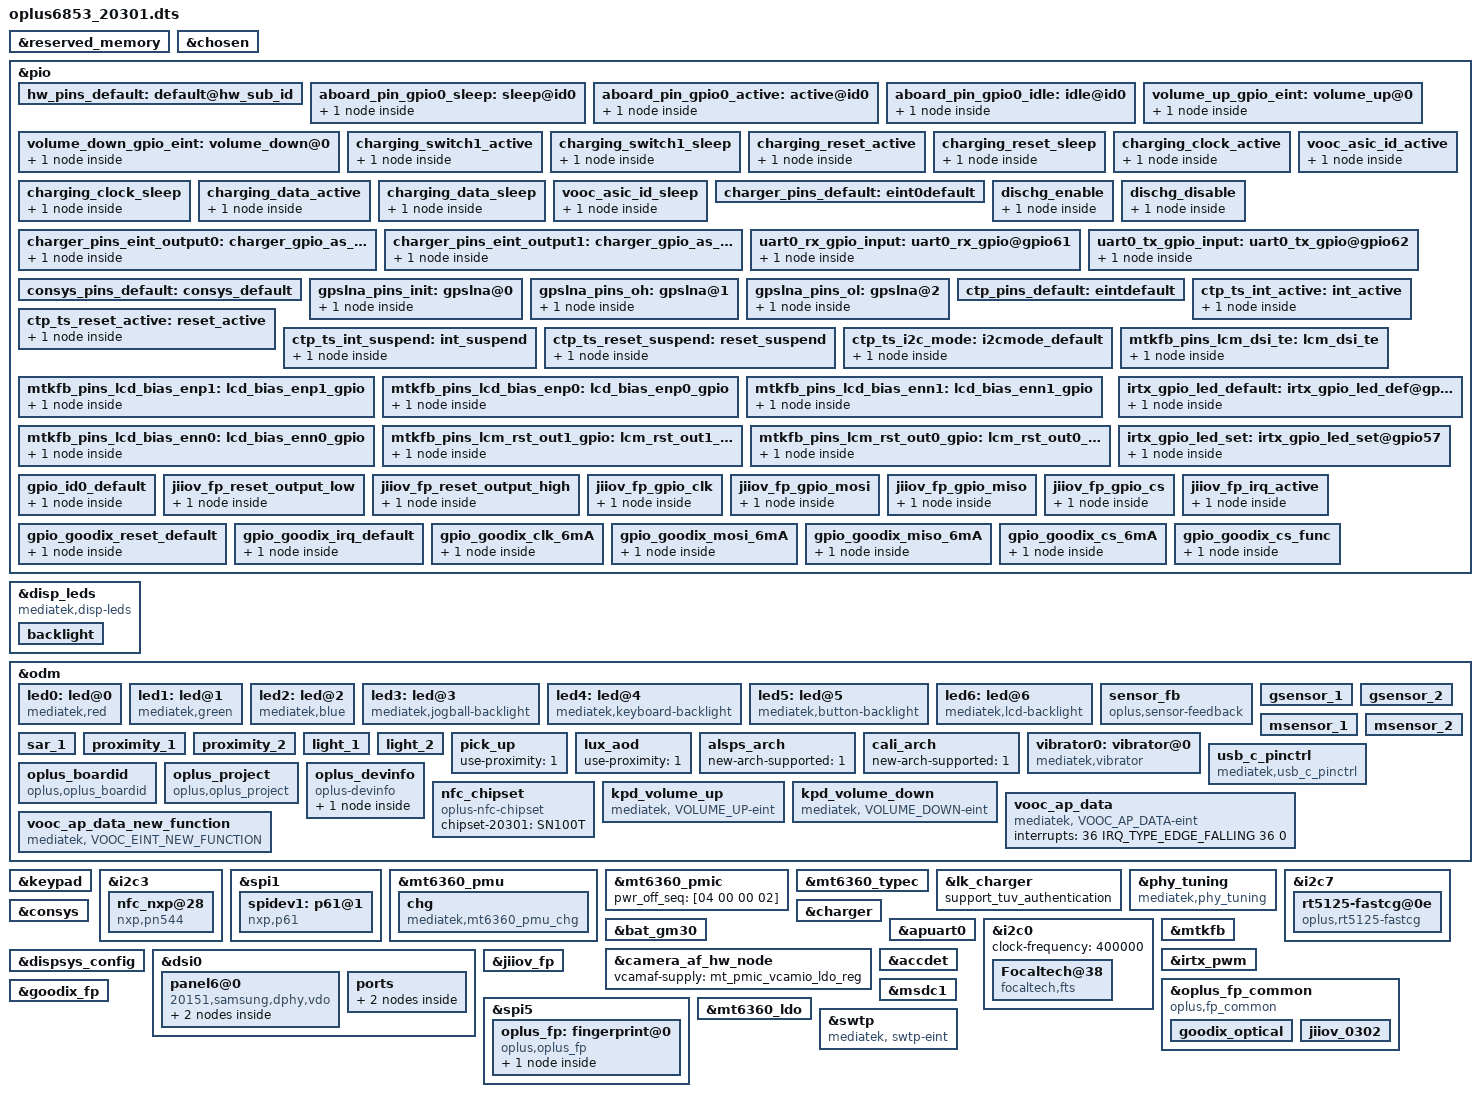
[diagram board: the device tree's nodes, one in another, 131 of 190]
/*
 * Mediatek's mt6853 SoC device tree source
 *
 * Copyright (C) 2016 MediaTek Inc.
 *
 * This program is free software; you can redistribute it and/or modify
 * it under the terms of the GNU General Public License version 2 as
 * published by the Free Software Foundation.
 *
 * This program is distributed in the hope that it will be useful,
 * but WITHOUT ANY WARRANTY; without even the implied warranty of
 * MERCHANTABILITY or FITNESS FOR A PARTICULAR PURPOSE.
 * See http://www.gnu.org/licenses/gpl-2.0.html for more details.
 */
/dts-v1/;
/plugin/;
#include <dt-bindings/interrupt-controller/irq.h>
#include <dt-bindings/interrupt-controller/arm-gic.h>
#include <dt-bindings/pinctrl/mt6853-pinfunc.h>

&reserved_memory {
};

/* chosen */
&chosen {

	atag,videolfb-fb_base_l = <0x7e605000>;
	atag,videolfb-fb_base_h = <0x0>;
	atag,videolfb-islcmfound = <1>;
	atag,videolfb-islcm_inited = <0>;
	atag,videolfb-fps= <6000>;
	atag,videolfb-vramSize= <0x1be0000>;
	atag,videolfb-lcmname=
		"nt35595_fhd_dsi_cmd_truly_nt50358_drv";
};
&pio {
        hw_pins_default:default@hw_sub_id {
        };

        aboard_pin_gpio0_sleep:sleep@id0 {
                pins_cmd_dat {
                        pinmux = <PINMUX_GPIO91__FUNC_GPIO91>;
                        slew-rate = <0>;
                        bias-pull-down;
                        input-enable;
                };
        };

        aboard_pin_gpio0_active:active@id0 {
                pins_cmd_dat {
                        pinmux = <PINMUX_GPIO91__FUNC_GPIO91>;
                        slew-rate = <0>;
                        bias-pull-up;
                        input-enable;
                };
        };

        aboard_pin_gpio0_idle:idle@id0 {
                pins_cmd_dat {
                        pinmux = <PINMUX_GPIO91__FUNC_GPIO91>;
                        slew-rate = <0>;
                        bias-disable;
                        input-enable;
                };
        };
};

&disp_leds {
	compatible = "mediatek,disp-leds";
	backlight {
		label = "lcd-backlight";
		max-brightness = <4095>;
		led-bits = <12>;
		trans-bits = <12>;
		default-state = "on";
	};
};

&odm {
	led0:led@0 {
		compatible = "mediatek,red";
		led_mode = <0>;
		data = <1>;
		pwm_config = <0 0 0 0 0>;
	};
	led1:led@1 {
		compatible = "mediatek,green";
		led_mode = <0>;
		data = <1>;
		pwm_config = <0 0 0 0 0>;
	};
	led2:led@2 {
		compatible = "mediatek,blue";
		led_mode = <0>;
		data = <1>;
		pwm_config = <0 0 0 0 0>;
	};
	led3:led@3 {
		compatible = "mediatek,jogball-backlight";
		led_mode = <0>;
		data = <1>;
		pwm_config = <0 0 0 0 0>;
	};
	led4:led@4 {
		compatible = "mediatek,keyboard-backlight";
		led_mode = <0>;
		data = <1>;
		pwm_config = <0 0 0 0 0>;
	};
	led5:led@5 {
		compatible = "mediatek,button-backlight";
		led_mode = <0>;
		data = <1>;
		pwm_config = <0 0 0 0 0>;
	};
	led6:led@6 {
		compatible = "mediatek,lcd-backlight";
		led_mode = <4>;
		data = <1>;
		pwm_config = <0 1 0 0 0>;
	};

	sensor_fb: sensor_fb {
		compatible = "oplus,sensor-feedback";
	};

	/*
	enum {
		LIS3DH,
		LSM6DS3,
		BMI160,
		LIS2HH12,
		LSM6DSM,
		BMI2XY,
		LSM6DSO,
		ICM4X6XX,
	};
	*/
	gsensor_1: gsensor_1 {
		status = "okay";
		sensor_name = <2>;//BMI160
		device_name = "bmi160";
		i2c_num = <2>;
		i2c_addr = <0>;
		direction = <3>;
		eint_num = <3>;
		step_count_7_en = <1>;
		config_miso = <1>;
		correct_y_bias = <0>;
		gyro_cali_version= <2>;
		acc_cali_range= <250 250 250>; //250mg
		gyro_cali_range= <350>;
	};

	gsensor_2: gsensor_2 {
		status = "okay";
		sensor_name = <4>;//LSM6DS3_c
		device_name = "lsm6dsm";
		i2c_num = <2>;
		i2c_addr = <0>;
		direction = <0>;
		eint_num = <3>;
		gyro_cali_version= <2>;
		acc_cali_range= <200 200 200>; //250mg
		gyro_cali_range= <700>;
	};
	/*
	enum {
		AKM09911,
		MMC3530,
		MMC5603,
		MXG4300,
	};
	*/
	msensor_1: msensor_1 {
		status = "okay";
		sensor_name = <0>;//AKM09911
		i2c_num = <0>;
		i2c_addr = <12>;
		direction = <5>;
		eint_num = <0>;
		soft-mag-parameter = <8507 0 1922 0 15 1 640 0 10513 0 39 1 1482 0 281 1 10130 0>;
	};
	msensor_2: msensor_2 {
		status = "okay";
		sensor_name = <3>;//MXG4300
		i2c_num = <0>;
		i2c_addr = <12>;
		direction = <5>;
		eint_num = <0>;
		soft-mag-parameter = <10000 0 0 0 0 0 0 0 10000 0 0 0 0 0 0 0 10000 0>;
	};

	/*
	enum {
		SX933x
	};
	*/
	sar_1: sar_1 {
		status = "okay";
		sensor_name = <0>;//SX933x
		i2c_num = <0>;
		i2c_addr = <40>;
		direction = <4>;
		eint_num = <13>;
		channel_num = <2>;
		channel_0_min = <4232>;
		channel_0_max = <6348>;
		channel_1_min = <2697>;
		channel_1_max = <4045>;
		channel_2_min = <0>;
		channel_2_max = <70000>;
		channel_3_min = <0>;
		channel_3_max = <70000>;
	};

	/*
	enum {
		TMD2725,
		APSD9922,
		STK3335,
		STK3331,
		STK2232,
		TCS3701,
		STK32600,
	};
	*/
	proximity_1: proximity_1 {
		status = "okay";
		sensor_name = <6>;//STK32600
		i2c_num = <0>;
		i2c_addr = <72>;
		direction = <4>;
		eint_num = <2>;
		low_step = <300>;
		high_step = <400>;
		low_limit = <650>;
		high_limit = <1050>;
		dirty_low_step = <300>;
		dirty_high_step = <400>;
		ps_dirty_limit = <1800>;
		ps_ir_limit = <2000>;
		ps_adjust_min = <0>;
		ps_adjust_max = <1850>;
		sampling_count = <5>;
		step_max = <400>;
		step_min = <100>;
		step_div = <2000>;
		anti_shake_delta = <70>;
		dynamic_cali_max = <2000>;
		raw2offset_radio = <1000>;
		offset_max = <60000>;
		offset_range_min = <0>;
		offset_range_max = <65534>;
		force_cali_limit = <2000>;
		cali_jitter_limit = <20>;
		cal_offset_margin = <3000>;
		sensor-reg = <0x03 0x30>;
	};
	proximity_2: proximity_2 {
		status = "okay";
		sensor_name = <5>;//TCS3701
		i2c_num = <0>;
		i2c_addr = <57>;
		direction = <4>;
		eint_num = <2>;
		low_step = <300>;
		high_step = <400>;
		low_limit = <400>;
		high_limit = <600>;
		dirty_low_step = <100>;
		dirty_high_step = <150>;
		ps_dirty_limit = <1022>;
		ps_ir_limit = <500>;
		ps_adjust_min = <0>;
		ps_adjust_max = <600>;
		sampling_count = <5>;
		step_max = <400>;
		step_min = <110>;
		step_div = <1500>;
		anti_shake_delta = <80>;
		dynamic_cali_max = <1023>;
		raw2offset_radio = <31200>;
		offset_max = <250>;
		offset_range_min = <255>;
		offset_range_max = <255>;
		force_cali_limit = <2000>;
		cali_jitter_limit = <30>;
		cal_offset_margin = <120>;
	};
	light_1: light_1 {
		status = "okay";
		sensor_name = <6>;//STK32600
		i2c_num = <0>;
		i2c_addr = <72>;
		direction = <4>;
		eint_num = <2>;
		als_buffer_length =<8>;
		als_ratio = <105>;
		device_name = "stk32600";
		als_type = <2>;
		als_spectral_coefficient = <1000>;
	};
	light_2: light_2 {
		status = "okay";
		sensor_name = <5>;//TCS3701
		i2c_num = <0>;
		i2c_addr = <57>;
		direction = <4>;
		eint_num = <2>;
		als_buffer_length = <10>;
		als_ratio = <110>;
                device_name = "tcs3701";
	};
	pick_up: pick_up {
		status = "okay";
		use-proximity = <1>;
	};
	lux_aod: lux_aod {
		status = "okay";
		use-proximity = <1>;
	};
	alsps_arch: alsps_arch {
		status = "okay";
		new-arch-supported = <1>;
	};
	cali_arch: cali_arch {
		status = "okay";
		new-arch-supported = <1>;
	};
	vibrator0:vibrator@0 {
		compatible = "mediatek,vibrator";
		//#ifdef OPLUS_FEATURE_CHG_BASIC
		vib_timer = <30>;
		vib_limit = <0>;
		//#endif
		vib_vol= <9>;
	};
	usb_c_pinctrl:usb_c_pinctrl {
		compatible = "mediatek,usb_c_pinctrl";
	};
	oplus_boardid:oplus_boardid {
		compatible = "oplus,oplus_boardid";
		oplus_boardid,dtsino="20301";//only one u32
		oplus_boardid,pcbmask="0xffff";//all mask 0xffff
	};
	oplus_project:oplus_project {
		compatible = "oplus,oplus_project";
	};
	oplus_devinfo:oplus_devinfo {
		compatible = "oplus-devinfo";
		pinctrl-names = "default", "aboard_gpio0_sleep", "aboard_gpio0_active", "aboard_gpio0_idle";
		pinctrl-0 = <&hw_pins_default>;
		pinctrl-1 = <&aboard_pin_gpio0_sleep>;
		pinctrl-2 = <&aboard_pin_gpio0_active>;
		pinctrl-3 = <&aboard_pin_gpio0_idle>;
		main-sub {
			use_tristate_gpio;
			compatible = "hw-match, main-sub";
			aboard-gpio0 = <&pio 91 0x00>;
			aboard-patterns = <0 2 1>;	/*0[high-resistance] 1[pull-down] 2[pull-up]*/
			/*main board*/
			match-projects = <20151 20301 20302>;
		};
	};

//#ifdef OPLUS_FEATURE_NFC_CONSOFT
    nfc_chipset:nfc_chipset {
        compatible = "oplus-nfc-chipset";
        chipset-20301 = "SN100T";
    };
//#endif /* OPLUS_FEATURE_NFC_CONSOFT */

/*OPLUS_FEAUTRE_KEYPAD keypad start*/
	kpd_volume_up:kpd_volume_up {
		compatible = "mediatek, VOLUME_UP-eint";
		interrupt-parent = <&pio>;
		interrupts = <1 IRQ_TYPE_EDGE_FALLING 1 0>;
		debounce = <32000>;
		status = "okay";
	};

	kpd_volume_down:kpd_volume_down {
		compatible = "mediatek, VOLUME_DOWN-eint";
		interrupt-parent = <&pio>;
		interrupts = <80 IRQ_TYPE_EDGE_FALLING 80 0>;
		debounce = <32000>;
		status = "okay";
	};
/*OPLUS_FEAUTRE_KEYPAD keypad end*/
};
/*OPLUS_FEAUTRE_KEYPAD keypad start*/
&keypad {
	keypad,volume-up	= <&pio 1 0x00>;
	keypad,volume-down	= <&pio 80 0x00>;
	pinctrl-names = "volume_up_as_int", "volume_down_as_int";
	pinctrl-0 = <&volume_up_gpio_eint>;
	pinctrl-1 = <&volume_down_gpio_eint>;
	status = "okay";
};

//#ifdef OPLUS_FEATURE_NFC_BRINGUP
&i2c3 {
       status = "okay";
       nfc_nxp@28 {
               compatible = "nxp,pn544";
               reg = <0x28>;
               nxp,pn544-irq = <&pio 5 0x0>;
               nxp,pn544-ven = <&pio 175 0x0>;
               nxp,pn544-fw-dwnld = <&pio 140 0x0>;
               nxp,pn544-clkreq = <&pio 81 0x0>;
               interrupt-parent = <&pio>;
       };
};

&spi1 {
       status = "okay";
       #address-cells = <1>;
       #size-cells = <0>;
       spidev1: p61@1 {
       compatible = "nxp,p61";
       reg = <0>;
       spi-max-frequency = <19200000>;
       };
};
//#endif /* OPLUS_FEATURE_NFC_BRINGUP */

&pio {
	volume_up_gpio_eint:volume_up@0{
		pins_cmd_dat {
			pinmux = <PINMUX_GPIO1__FUNC_GPIO1>;
			slew-rate = <0>;  /*direction 0:in, 1:out*/
			input-enable;
		};
	};

	volume_down_gpio_eint:volume_down@0{
		pins_cmd_dat {
			pinmux = <PINMUX_GPIO80__FUNC_GPIO80>;
			slew-rate = <0>;  /*direction 0:in, 1:out*/
			input-enable;
		};
	};
};
/*OPLUS_FEAUTRE_KEYPAD keypad end*/

/* Charging Start */
&mt6360_pmu {
	mt6360,intr_gpio_num = <10>; /* direct defined GPIO num */
	mt6360,intr_gpio = <&pio 10 0x0>;
	disable_lpsd = <1>;
};

&mt6360_pmic {
	pwr_off_seq = [04 00 00 02];
};

&mt6360_typec {
	mt6360pd,intr_gpio_num = <9>; /* direct defined GPIO num */
	mt6360pd,intr_gpio = <&pio 9 0x0>;
};

&mt6360_pmu {
	chg {
		compatible = "mediatek,mt6360_pmu_chg";
		interrupt-parent = <&mt6360_pmu>;
		interrupts = <4 0>, <6 0>, <7 0>, <9 0>,
				<12 0>, <13 0>, <14 0>, <15 0>,
				<27 0>, <29 0>, <30 0>, <32 0>,
				<35 0>, <40 0>, <48 0>, <60 0>,
				<53 0>;
		interrupt-names = "chg_treg_evt", "chg_mivr_evt",
				"pwr_rdy_evt", "chg_batsysuv_evt",
				"chg_vsysuv_evt", "chg_vsysov_evt",
				"chg_vbatov_evt", "chg_vbusov_evt",
				"chg_tmri", "chg_adpbadi",
				"chg_rvpi",  "chg_aiccmeasl",
				"wdtmri", "pumpx_donei",
				"attachi", "chrdet_ext_evt",
				"hvdcp_det";
		io-channels = <&adc 0>, <&adc 1>, <&adc 3>, <&adc 4>,
				<&adc 5>, <&adc 6>, <&adc 8>, <&adc 10>;
		io-channel-names = "USBID", "VBUSDIV5", "VSYS", "VBAT",
				"IBUS", "IBAT", "TEMP_JC", "TS";
		chg_name = "primary_chg";
		ichg = <2000000>;               /* uA */
		aicr = <500000>;                /* uA */
		mivr = <4400000>;               /* uV */
		cv = <4350000>;                 /* uA */
		ieoc = <150000>;                /* uA */
		safety_timer = <12>;            /* hour */
		ircmp_resistor = <25000>;       /* uohm */
		ircmp_vclamp = <32000>;         /* uV */
		en_te = <1>;
		en_wdt = <1>;
		aicc_once = <1>;
		post_aicc = <1>;
		batoc_notify = <0>;
	};
};

/*#ifdef OPLUS_FEATURE_CHG_BASIC*/
&lk_charger{
	support_tuv_authentication;
};
/*#endif*/

&phy_tuning {
	compatible = "mediatek,phy_tuning";
	u2_vrt_ref = <7>;
	u2_term_ref = <6>;
	u2_enhance = <2>;

	host_u2_vrt_ref = <5>;
	host_u2_term_ref = <1>;
	host_u2_enhance = <1>;
};

&i2c7 {
	rt5125-fastcg@0e{
		status = "okay";
		compatible = "oplus,rt5125-fastcg";
		reg = <0x0e>;
		qcom,vooc_reply_mcu_bits = <7>;
		qcom,oplus_batt_4400mv;
		qcom,vooc-low-temp = <0>;
		qcom,vooc-high-temp = <430>;
		qcom,vooc-high-soc = <90>;
		qcom,vooc_cool_bat_volt = <3650>;
		qcom,vooc_little_cool_bat_volt = <3550>;
		qcom,vooc_normal_bat_volt = <3450>;
		qcom,vooc_warm_bat_volt = <3350>;

		qcom,vooc_cool_bat_suspend_volt = <3650>;
		qcom,vooc_little_cool_bat_suspend_volt = <3550>;
		qcom,vooc_normal_bat_suspend_volt = <3450>;
		qcom,vooc_warm_bat_suspend_volt = <3350>;
		qcom,vooc_fw_update_newmethod;
		qcom,vooc-fw-type = <2>;
		qcom,vooc_is_platform_gauge;
		qcom,vooc_multistep_adjust_current_support;
		qcom,vooc_multistep_initial_batt_temp = <1000>;
		qcom,vooc_strategy_normal_current = <0x0b>;

		qcom,vooc_strategy1_batt_high_temp0 = <410>;
		qcom,vooc_strategy1_batt_high_temp1 = <425>;
		qcom,vooc_strategy1_batt_high_temp2 = <435>;
		qcom,vooc_strategy1_batt_low_temp2 = <430>;
		qcom,vooc_strategy1_batt_low_temp1 = <410>;
		qcom,vooc_strategy1_batt_low_temp0 = <390>;

		qcom,vooc_strategy1_high_current0 = <0x07>;//4A
		qcom,vooc_strategy1_high_current1 = <0x05>;//3A
		qcom,vooc_strategy1_high_current2 = <0x04>;//2A
		qcom,vooc_strategy1_low_current2 = <0x05>;//3A
		qcom,vooc_strategy1_low_current1 = <0x09>;//5A
		qcom,vooc_strategy1_low_current0 = <0x0b>;//6A

		qcom,vooc_current_lvl = <1000
									1500
									2000
									2500
									3000
									3500
									4000
									4500
									5000
									5500
									6000
									6500
									7000
									7500
									8000
									8500
									9000
									9500
									10000
									10500
									11000
									11500
									12000
									12500>;

		pinctrl-names = "switch1_act_switch2_act", "switch1_sleep_switch2_sleep",
						"switch1_act_switch3_act", "switch1_sleep_switch3_sleep",
						"switch1_act_switch2_sleep", "switch1_sleep_switch2_act",
						"clock_active","clock_sleep",
						"data_active","data_sleep",
						"reset_active","reset_sleep",
						"vooc_asic_id_active","vooc_asic_id_sleep";
		pinctrl-0 = <&charging_switch1_active>;
		pinctrl-1 = <&charging_switch1_sleep>;
		pinctrl-2 = <&charging_switch1_active>;
		pinctrl-3 = <&charging_switch1_sleep>;
		pinctrl-4 = <&charging_switch1_active>;
		pinctrl-5 = <&charging_switch1_sleep>;
		pinctrl-6 = <&charging_clock_active>;
		pinctrl-7 = <&charging_clock_sleep>;
		pinctrl-8 = <&charging_data_active>;
		pinctrl-9 = <&charging_data_sleep>;
		pinctrl-10 = <&charging_reset_active>;
		pinctrl-11 = <&charging_reset_sleep>;
		pinctrl-12 = <&vooc_asic_id_active>;
		pinctrl-13 = <&vooc_asic_id_sleep>;

		qcom,charging_switch1-gpio 		= <&pio 32 0x00>;              //SW_CTRL
		//qcom,charging_switch1_ctr1-gpio 	= <&pio 148 0x00>;

		qcom,charging_reset-gpio 			= <&pio 132 0x00>;         //mcu_en
		qcom,charging_clock-gpio 			= <&pio 35 0x00>;          //ap_clk
		qcom,charging_data-gpio 			= <&pio 36 0x00>;          //ap_data
		qcom,vooc_asic_id-gpio				= <&pio 92 0x00>;
	};

};

&pio {
	charging_switch1_active: charging_switch1_active {
		pins_cmd_dat {
			pinmux = <PINMUX_GPIO32__FUNC_GPIO32>;
			slew-rate = <1>;
			output-high;
		};
	};

	charging_switch1_sleep: charging_switch1_sleep {
		pins_cmd_dat {
			pinmux = <PINMUX_GPIO32__FUNC_GPIO32>;
			slew-rate = <1>;
			output-low;
		};
	};

	/*charging_switch1_ctr1_active: charging_switch1_ctr1_active {
		pins_cmd_dat {
			pinmux = <PINMUX_GPIO127__FUNC_GPIO127>;
			slew-rate = <1>;
			output-high;
		};
	};
	charging_switch1_ctr1_sleep: charging_switch1_ctr1_sleep {
		pins_cmd_dat {
			pinmux = <PINMUX_GPIO127__FUNC_GPIO127>;
			slew-rate = <1>;
			output-low;
		};
	};*/

	charging_reset_active: charging_reset_active {
		pins_cmd_dat {
			pinmux = <PINMUX_GPIO132__FUNC_GPIO132>;
			slew-rate = <1>;
			output-high;
		};
	};

	charging_reset_sleep: charging_reset_sleep {
		pins_cmd_dat {
			pinmux = <PINMUX_GPIO132__FUNC_GPIO132>;
			slew-rate = <1>;
			output-low;
		};
	};

	charging_clock_active: charging_clock_active {
		pins_cmd_dat {
			pinmux = <PINMUX_GPIO35__FUNC_GPIO35>;
			slew-rate = <0>;
			bias-pull-up;
		};
	};

	charging_clock_sleep: charging_clock_sleep {
		pins_cmd_dat {
			pinmux = <PINMUX_GPIO35__FUNC_GPIO35>;
			slew-rate = <0>;
			bias-pull-down;
		};
	};

	charging_data_active: charging_data_active {
		pins_cmd_dat {
			pinmux = <PINMUX_GPIO36__FUNC_GPIO36>;
			slew-rate = <0>;
			bias-pull-down;
		};
	};

	charging_data_sleep: charging_data_sleep {
		pins_cmd_dat {
			pinmux = <PINMUX_GPIO36__FUNC_GPIO36>;
			slew-rate = <0>;
			bias-pull-down;
		};
	};

	vooc_asic_id_active: vooc_asic_id_active {
		pins_cmd_dat {
			pinmux = <PINMUX_GPIO92__FUNC_GPIO92>;
			input-enable;
			slew-rate = <0>;
			bias-pull-up;
		};
	};
	vooc_asic_id_sleep: vooc_asic_id_sleep {
		pins_cmd_dat {
			pinmux = <PINMUX_GPIO92__FUNC_GPIO92>;
			input-enable;
			slew-rate = <0>;
			bias-pull-down;
		};
	};

};

&odm {
	vooc_ap_data:vooc_ap_data {
		compatible = "mediatek, VOOC_AP_DATA-eint";
		interrupts = <36 IRQ_TYPE_EDGE_FALLING 36 0>;
	};
	vooc_ap_data_new_function:vooc_ap_data_new_function {
		compatible = "mediatek, VOOC_EINT_NEW_FUNCTION";
	};
	/*cp_low_current:cp_low_current {
		compatible = "mediatek, CP_LOW_CURRENT-eint";
		interrupts = <12 IRQ_TYPE_EDGE_FALLING 12 0>;
	};
	cp_low_current_new_function:cp_low_current_new_function {
		compatible = "mediatek,  CP_LOW_CURRENT_EINT_NEW_FUNCTION";
	};*/

};

&charger {
	io-channels =  <&auxadc 3>,<&auxadc 4>,
		<&auxadc 5>;
	io-channel-names = "auxadc3-chargeric_temp","auxadc4-usb_temp_v_l",
		"auxadc5-usb_temp_v_r";

	pinctrl-names = "default", "dischg_enable", "dischg_disable" ,"charger_gpio_as_output_low", "charger_gpio_as_output_high";
	pinctrl-0 = <&charger_pins_default>;
	pinctrl-1 = <&dischg_enable>;
	pinctrl-2 = <&dischg_disable>;
	pinctrl-3 = <&charger_pins_eint_output0>;      //USB_ON -> USB_SWITCH:(UART && USB)
	pinctrl-4 = <&charger_pins_eint_output1>;


	//for oplus chg framework:
	qcom,input_current_charger_ma = <2000>;
	qcom,input_current_usb_ma = <500>;
	qcom,input_current_cdp_ma = <1500>;
	qcom,input_current_led_ma = <1200>;
	qcom,input_current_led_ma_high = <1200>;
	qcom,input_current_led_ma_warm = <1500>;
	qcom,input_current_led_ma_normal = <2000>;
	qcom,input_current_led_ma_forcmcc = <500>;
	qcom,input_current_camera_ma = <2000>;
	qcom,input_current_calling_ma = <1500>;
	qcom,pd_input_current_charger_ma = <3000>;

	qcom,iterm_disabled = <0>;
	qcom,iterm_ma = <221>;
	qcom,recharge-mv = <100>;

	qcom,batt_capacity_mah = <4310>; /*typical capacity*/
	//qcom,batt_capacity_mah = <4220>; /*rated capacity*/

	qcom,removed_bat_decidegc = <190>;  /* < -19C */

	qcom,cold_bat_decidegc = <20>;  /* -2C ~ 0C */
	qcom,temp_cold_vfloat_mv = <3980>;
	qcom,temp_cold_fastchg_current_ma = <300>;

	qcom,little_cold_bat_decidegc = <0>;    /* 0C ~ 5C */
	qcom,temp_little_cold_vfloat_mv = <4435>;
	qcom,temp_little_cold_fastchg_current_ma_high = <1850>;
	qcom,temp_little_cold_fastchg_current_ma_low = <1100>;
	qcom,temp_little_cold_fastchg_current_ma = <1100>;
	qcom,pd_temp_little_cold_fastchg_current_ma_high = <1850>;
	qcom,pd_temp_little_cold_fastchg_current_ma_low = <1100>;

	qcom,cool_bat_decidegc = <50>;  /* 5C ~ 12C */
	qcom,temp_cool_vfloat_mv = <4435>;
	qcom,temp_cool_fastchg_current_ma_high = <2200>;
	qcom,temp_cool_fastchg_current_ma_low = <1850>;
	qcom,pd_temp_cool_fastchg_current_ma_high = <2600>;
	qcom,pd_temp_cool_fastchg_current_ma_low = <1850>;

	qcom,little_cool_bat_decidegc = <120>;  /* 12C ~ 16C */
	qcom,temp_little_cool_vfloat_mv = <4435>;
	qcom,temp_little_cool_fastchg_current_ma = <2200>;
	qcom,pd_temp_little_cool_fastchg_current_ma = <3200>;

	qcom,normal_bat_decidegc = <160>;       /* 16C ~ 45C */
	qcom,temp_normal_fastchg_current_ma = <2600>;
	qcom,temp_normal_vfloat_mv = <4435>;
	qcom,pd_temp_normal_fastchg_current_ma = <3200>;

	qcom,warm_bat_decidegc = <450>;         /* 45C ~ 53C */ /*8pin Bat Vooc project need add 3 degree C*/
	qcom,temp_warm_vfloat_mv = <4130>;
	qcom,temp_warm_fastchg_current_ma = <1100>;
	qcom,temp_warm_fastchg_current_ma_led_on = <500>;
	qcom,pd_temp_warm_fastchg_current_ma = <1100>;

	qcom,hot_bat_decidegc = <530>;  /* > 53C */

	qcom,non_standard_vfloat_mv = <3980>;
	qcom,non_standard_fastchg_current_ma = <512>;

	qcom,short_c_bat_cv_mv = <4330>;
	qcom,short_c_bat_vfloat_mv = <3800>;
	qcom,short_c_bat_fastchg_current_ma = <512>;
	qcom,short_c_bat_vfloat_sw_limit = <3750>;

	qcom,cold_vfloat_sw_limit = <3930>;
	qcom,little_cold_vfloat_sw_limit = <4385>;
	qcom,cool_vfloat_sw_limit = <4385>;
	qcom,little_cool_vfloat_sw_limit = <4385>;
	qcom,normal_vfloat_sw_limit = <4385>;
	qcom,warm_vfloat_sw_limit = <4080>;
	qcom,non_standard_vfloat_sw_limit = <3930>;

	qcom,max_chg_time_sec = <36000>;
	qcom,charger_hv_thr = <5900>;
	qcom,charger_recv_thr = <5500>;
	qcom,charger_lv_thr = <3400>;
	qcom,vbatt_full_thr = <4400>;
	qcom,vbatt_hv_thr = <4550>;

	qcom,vfloat_step_mv = <8>;
	qcom,non_standard_vfloat_over_sw_limit = <3990>;
	qcom,cold_vfloat_over_sw_limit = <3990>;
	qcom,little_cold_vfloat_over_sw_limit = <4445>;
	qcom,cool_vfloat_over_sw_limit = <4445>;
	qcom,little_cool_vfloat_over_sw_limit = <4445>;
	qcom,normal_vfloat_over_sw_limit = <4445>;
	qcom,warm_vfloat_over_sw_limit = <4140>;

	qcom,vbatt_power_off = <3300>;
	qcom,vbatt_soc_1 = <3410>;
	qcom,vooc_project = <1>;
	qcom,vbatt_num = <1>;
	qcom,internal_gauge_with_asic = <1>;
	qcom,ffc_support;
	qcom,chargerid_support;

	qcom,normal_vterm_hw_inc = <18>;
	qcom,non_normal_vterm_hw_inc = <18>;

	qcom,ff1_normal_fastchg_ma = <1400>;
	qcom,ff1_warm_fastchg_ma = <1500>;	/* 35C ~ 40c */
	qcom,ff1_exit_step_ma = <150>;
	qcom,ff1_warm_exit_step_ma = <150>;
	qcom,ffc2_normal_fastchg_ma = <1400>;/*16C~35c*/
	qcom,ffc2_warm_fastchg_ma = <1500>;	/* 35C ~ 40c */
	qcom,ffc2_temp_warm_decidegc = <350>;
	qcom,ffc2_temp_high_decidegc = <400>;
	qcom,ffc2_temp_low_decidegc = <160>;
	qcom,ffc2_exit_step_ma = <150>;
	qcom,ffc2_warm_exit_step_ma = <150>;

	qcom,ffc_normal_vfloat_sw_limit = <4485>;
	qcom,ffc2_normal_vfloat_sw_limit = <4485>;
	qcom,ffc_temp_normal_vfloat_mv = <4550>;
	qcom,ffc_normal_vfloat_over_sw_limit = <4550>;

	qcom,overchg_normal_fastchg_ma = <700>;/*16C~35c*/
	qcom,overchg_temp_warm_decidegc = <350>;
	qcom,overchg_warm_fastchg_ma = <750>;/*35C~40c*/
	qcom,overchg_temp_high_decidegc = <400>;

	qcom,overchg_normal_vfloat_sw_limit = <4450>;
	qcom,overchg_temp_normal_vfloat_mv = <4500>;
	qcom,overchg_normal_vfloat_over_sw_limit = <4500>;

	qcom,default_iterm_ma = <221>;
	qcom,default_temp_normal_fastchg_current_ma = <2000>;
	qcom,default_normal_vfloat_sw_limit = <4385>;
	qcom,default_temp_normal_vfloat_mv = <4435>;
	qcom,default_normal_vfloat_over_sw_limit = <4445>;

	//for control:
	//qcom,suspend_after_full;
	qcom,check_batt_full_by_sw;
	//qcom,external_gauge;
	qcom,chg_ctrl_by_calling;
	qcom,chg_ctrl_by_lcd;
	qcom,chg_ctrl_by_camera;
	qcom,sw_vfloat_over_protect_enable;
	qcom,support_ntc_01c_precision;
	qcom,smart_charging_screenoff;
	qcom,usbtemp_lowvbus_detect;
	qcom,vooc_show_ui_soc_decimal;
	qcom,ui_soc_decimal_speedmin = <20>;

	//GPIO config:
	qcom,chargerid_switch-gpio = <&pio 46 0x00>;
	qcom,dischg-gpio = <&pio 44 0x00>;
};

&bat_gm30 {
	FUELGAGUE_APPLY = <(1)>;
	IS_4450MV_BATTERY_SUPPORT = <(1)>;
	ENABLE_IS_FORCE_FULL = <1>;
	io-channels = <&auxadc 6>;
	io-channel-names = "auxadc6-batt_id_v";
	/*bat_id channel*/
	CAR_TUNE_VALUE = <(99)>;
	/*The resistance of PCB*/
	R_FG_VALUE = <(5)>;
	/*R_sense resistance*/
	g_FG_PSEUDO100_T0 = <(98)>;
/*	Pseudo 100% percentage at T0*/
	g_FG_PSEUDO100_T1 = <(98)>;
/*	Pseudo 100% percentage at T1*/
	g_FG_PSEUDO100_T2 = <(98)>;
/*	Pseudo 100% percentage at T2*/
	g_FG_PSEUDO100_T3 = <(94)>;
/*	Pseudo 100% percentage at T3*/
	#include "mediatek/bat_setting/mt6853_20151_battery_table.dtsi"
	#include "mediatek/bat_setting/mt6853_20151_battery_prop_dim2_ext.dtsi"
	/*zcv table*/
};

&pio {
	charger_pins_default: eint0default {
	};

	dischg_enable: dischg_enable {
		pins_cmd_dat {
			pinmux = <PINMUX_GPIO44__FUNC_GPIO44>;
			slew-rate = <1>;           //0:input direction 1:output direction
			//bias-pull-up = <00>;
			output-high;
		};
	};

	dischg_disable: dischg_disable {
		pins_cmd_dat {
			pinmux = <PINMUX_GPIO44__FUNC_GPIO44>;
			slew-rate = <1>;
			//bias-pull-down = <00>;
			output-low;
		};
	};

	charger_pins_eint_output0: charger_gpio_as_output_low {
		pins_cmd_dat {
			pinmux = <PINMUX_GPIO46__FUNC_GPIO46>;
			slew-rate = <1>;
			output-low;
		};
	};
	charger_pins_eint_output1: charger_gpio_as_output_high {
		pins_cmd_dat {
			pinmux = <PINMUX_GPIO46__FUNC_GPIO46>;
			slew-rate = <1>;
			output-high;
		};
	};

};

&apuart0 {
	pinctrl-names = "uart0_rx_gpio",
			"uart0_tx_gpio";
	pinctrl-0 = <&uart0_rx_gpio_input>;
	pinctrl-1 = <&uart0_tx_gpio_input>;
	status = "okay";
};

&pio {
	uart0_rx_gpio_input:uart0_rx_gpio@gpio61 {
		pins_cmd_dat {
			pinmux = <PINMUX_GPIO61__FUNC_GPIO61>;
			input-enable;
			slew-rate = <0>;
			bias-disable;
		};
	};
	uart0_tx_gpio_input:uart0_tx_gpio@gpio62 {
		pins_cmd_dat {
			pinmux = <PINMUX_GPIO62__FUNC_GPIO62>;
			input-enable;
			slew-rate = <0>;
			bias-disable;
		};
	};
};

/* Charging end  */

/* USB SWITCH GPIO start */
//&pio {
//	usb_default: usb_default {
//	};
//
//	gpio_redriver_c1_init: c1_init {
//		pins_cmd_dat {
//			pinmux = <PINMUX_GPIO41__FUNC_GPIO41>;
//			slew-rate = <1>;
//			output-low;
//		};
//	};
//
//	gpio_redriver_c1_low: c1_low {
//		pins_cmd_dat {
//			pinmux = <PINMUX_GPIO41__FUNC_GPIO41>;
//			slew-rate = <1>;
//			output-low;
//		};
//	};
//
//	gpio_redriver_c1_hiz: c1_highz {
//		pins_cmd_dat {
//			pinmux = <PINMUX_GPIO41__FUNC_GPIO41>;
//			slew-rate= <0>;
//			bias-disable;
//		};
//	};
//
//	gpio_redriver_c1_high: c1_high {
//		pins_cmd_dat {
//			pinmux = <PINMUX_GPIO41__FUNC_GPIO41>;
//			slew-rate = <1>;
//			output-high;
//		};
//	};
//
//	gpio_redriver_c2_init: c2_init {
//		pins_cmd_dat {
//			pinmux = <PINMUX_GPIO40__FUNC_GPIO40>;
//			slew-rate = <1>;
//			output-low;
//		};
//	};
//
//	gpio_redriver_c2_low: c2_low {
//		pins_cmd_dat {
//			pinmux = <PINMUX_GPIO40__FUNC_GPIO40>;
//			slew-rate = <1>;
//			output-low;
//		};
//	};
//
//	gpio_redriver_c2_hiz: c2_highz {
//		pins_cmd_dat {
//			pinmux = <PINMUX_GPIO40__FUNC_GPIO40>;
//			slew-rate= <0>;
//			bias-disable;
//		};
//	};
//
//	gpio_redriver_c2_high: c2_high {
//		pins_cmd_dat {
//			pinmux = <PINMUX_GPIO40__FUNC_GPIO40>;
//			slew-rate = <1>;
//			output-high;
//		};
//	};
//
//	gpio_u3_switch_sel1: u3_sw_sel1 {
//		pins_cmd_dat {
//			pinmux = <PINMUX_GPIO11__FUNC_GPIO11>;
//			slew-rate = <1>;
//			output-low;
//		};
//	};
//
//	gpio_u3_switch_sel2: u3_sw_sel2 {
//		pins_cmd_dat {
//			pinmux = <PINMUX_GPIO11__FUNC_GPIO11>;
//			slew-rate = <1>;
//			output-high;
//		};
//	};
//
//	gpio_u3_switch_enable: u3_sw_en {
//	};
//
//	gpio_u3_switch_disable: u3_sw_dis {
//	};
//};
//
//&usb_c_pinctrl {
//	pinctrl-names = "usb_default",
//		"redrv_c1_init",
//		"redrv_c1_low",
//		"redrv_c1_hiz",
//		"redrv_c1_high",
//		"redrv_c2_init",
//		"redrv_c2_low",
//		"redrv_c2_hiz",
//		"redrv_c2_high",
//		"switch_sel1",
//		"switch_sel2",
//		"switch_enable",
//		"switch_disable";
//
//	pinctrl-0 = <&usb_default>;
//	pinctrl-1 = <&gpio_redriver_c1_init>;
//	pinctrl-2 = <&gpio_redriver_c1_low>;
//	pinctrl-3 = <&gpio_redriver_c1_hiz>;
//	pinctrl-4 = <&gpio_redriver_c1_high>;
//	pinctrl-5 = <&gpio_redriver_c2_init>;
//	pinctrl-6 = <&gpio_redriver_c2_low>;
//	pinctrl-7 = <&gpio_redriver_c2_hiz>;
//	pinctrl-8 = <&gpio_redriver_c2_high>;
//	pinctrl-9 = <&gpio_u3_switch_sel1>;
//	pinctrl-10 = <&gpio_u3_switch_sel2>;
//	pinctrl-11 = <&gpio_u3_switch_enable>;
//	pinctrl-12 = <&gpio_u3_switch_disable>;
//	status = "okay";
//
//	usb_switch-data {
//		en_pin_num = <0>;
//		en_pin_val = <0>;
//		sel_pin_num = <11>;
//		sel_pin_val = <1>;
//		c1_pin_num = <41>;
//		c1_pin_val = <2>;
//		c2_pin_num = <40>;
//		c2_pin_val = <1>;
//	};
//};
/* USB SWITCH GPIO end */

/* CONSYS GPIO standardization */
&pio {
	consys_pins_default: consys_default {
	};
	gpslna_pins_init: gpslna@0 {
		pins_cmd_dat {
			pinmux = <PINMUX_GPIO87__FUNC_GPIO87>;
			output-low;
		};
	};
	gpslna_pins_oh: gpslna@1 {
		pins_cmd_dat {
			pinmux = <PINMUX_GPIO87__FUNC_GPS_L1_ELNA_EN>;
		};
	};
	gpslna_pins_ol: gpslna@2 {
		pins_cmd_dat {
			pinmux = <PINMUX_GPIO87__FUNC_GPIO87>;
			output-low;
		};
	};
};

&consys {
	pinctrl-names = "default", "gps_lna_state_init",
		"gps_lna_state_oh", "gps_lna_state_ol";
	pinctrl-0 = <&consys_pins_default>;
	pinctrl-1 = <&gpslna_pins_init>;
	pinctrl-2 = <&gpslna_pins_oh>;
	pinctrl-3 = <&gpslna_pins_ol>;
	status = "okay";
};
/* CONSYS end */


/* TOUCH start */
/*#ifdef OPLUS_FEATURE_TP_BASIC*/
&i2c0 {
	clock-frequency = <400000>;
	status = "okay";
	Focaltech@38 {
		compatible = "focaltech,fts";
		reg = <0x38>;
		chip-name = "FT3518";

		/* Interrupt && Irq-gpio */
		interrupt-parent = <&pio>;
		interrupts = <14 IRQ_TYPE_EDGE_FALLING 14 0>;

		enable2v8_gpio = <&pio 138 0x1>;

		/* Other HW Resource */
		irq-gpio = <&pio 14 0x2002>;
		reset-gpio = <&pio 43 0>;
		pinctrl-names = "default";

		vid_len = <0>;
		tp_type = <8>;
		// type of tp_dev ,TP-SAMSUNG = 8;
		platform_support_project = <20151 20301 20302>;
		platform_support_project_dir = <20151 20151 20151>;
		platform_support_project_commandline = "oplus20151_samsung_ams643_1080p_dsi_vdo_lcm_drv","oplus20151_samsung_ams643_1080p_dsi_vdo_lcm_drv","oplus20151_samsung_ams643_1080p_dsi_vdo_lcm_drv";

		touchpanel,max-num-support = <10>;
		touchpanel,tx-rx-num = <16 34>;
		touchpanel,panel-coords = <4320 9600>;
		touchpanel,display-coords = <1080 2400>;
		touchpanel,touchmajor-limit = <0 216>;
		touchpanel,smooth-level = <255 2 15 25 45 60>;
		touchpanel,sensitive-level = <255 20 14 10 6 0>;

		/* SW Support Feature Control */
		black_gesture_support;
		fw_edge_limit_support;
		pressure_report_support;
		charger_pump_support;
		game_switch_support;
		smart_gesture_support;
		fw_update_app_support;
		fingerprint_underscreen_support;
		headset_pump_support;
		esd_handle_support;
		high_resolution_support;
		health_monitor_v2_support;
		/*
		 *Virtual Key Config:
		 *1:touchpanel,button-type: <virtualkey_type  supportted_button-map>
		 *virtualkey_type:
		 *Type 1: using board_properties
		 *Type 2: using same IC (button zone&& touch zone are seprate)
		 *Type 3: using diffrent IC (button zone&& touch zone are seprate)
		 *Type 4: No need of virtual key process
		 *supportted_button-map:select|menu|home|back
		 *
		 *2:touchpanel,button-map
		 *type (X1,Y1)(X2,Y2)(X3,Y3)(Width_X,Hight_Y)--Only when button-type is 0
		 */
		touchpanel,button-type = <4>;
		touchpanel.button-TRx = <0 0>;
	};
};
/*#endif OPLUS_FEATURE_TP_BASIC*/


&pio {
	ctp_pins_default: eintdefault {
	};
	ctp_ts_int_active: int_active {
		pins_cmd_dat {
			pinmux = <PINMUX_GPIO14__FUNC_GPIO14>;
			slew-rate = <0>;
			bias-pull-up = <11>;
		};
	};
	ctp_ts_reset_active: reset_active {
		pins_cmd_dat {
			pinmux = <PINMUX_GPIO43__FUNC_GPIO43>;
			slew-rate = <1>;
			output-high;
		};
	};
	ctp_ts_int_suspend: int_suspend {
		pins_cmd_dat {
			pinmux = <PINMUX_GPIO14__FUNC_GPIO14>;
			slew-rate = <1>;
			output-low;
		};
	};
	ctp_ts_reset_suspend: reset_suspend {
		pins_cmd_dat {
			pinmux = <PINMUX_GPIO43__FUNC_GPIO43>;
			slew-rate = <1>;
			output-low;
		};
	};
	ctp_ts_i2c_mode: i2cmode_default {
		pins_cmd_dat {
			pinmux = <PINMUX_GPIO97__FUNC_SCL0>,
				<PINMUX_GPIO98__FUNC_SDA0>;
		};
	};
};
/* TOUCH end */

//#include "mediatek/cust_mt6853_touch_1080x1920.dtsi"
#include "mediatek/cust_mt6853_camera_20301.dtsi"
#include <oplus6853_20301/cust.dtsi>
/* DISPSYS GPIO standardization */

#ifndef CONFIG_FPGA_EARLY_PORTING
&pio {
	mtkfb_pins_lcd_bias_enp1: lcd_bias_enp1_gpio {
		pins_cmd_dat {
			pinmux = <PINMUX_GPIO137__FUNC_GPIO137>;
			slew-rate = <1>;
			output-high;
		};
	};

	mtkfb_pins_lcd_bias_enp0: lcd_bias_enp0_gpio {
		pins_cmd_dat {
			pinmux = <PINMUX_GPIO137__FUNC_GPIO137>;
			slew-rate = <1>;
			output-low;
		};
	};

	mtkfb_pins_lcd_bias_enn1: lcd_bias_enn1_gpio {
		pins_cmd_dat {
			pinmux = <PINMUX_GPIO138__FUNC_GPIO138>;
			slew-rate = <1>;
			output-high;
		};
	};

	mtkfb_pins_lcd_bias_enn0: lcd_bias_enn0_gpio {
		pins_cmd_dat {
			pinmux = <PINMUX_GPIO138__FUNC_GPIO138>;
			slew-rate = <1>;
			output-low;
		};
	};

	mtkfb_pins_lcm_rst_out1_gpio: lcm_rst_out1_gpio {
		pins_cmd_dat {
			pinmux = <PINMUX_GPIO86__FUNC_GPIO86>;
			slew-rate = <1>;
			output-high;
		};
	};

	mtkfb_pins_lcm_rst_out0_gpio: lcm_rst_out0_gpio {
		pins_cmd_dat {
			pinmux = <PINMUX_GPIO86__FUNC_GPIO86>;
			slew-rate = <1>;
			output-low;
		};
	};
	mtkfb_pins_lcm_dsi_te: lcm_dsi_te {
		pins_cmd_dat {
			pinmux = <PINMUX_GPIO84__FUNC_DSI_TE>;
		};
	};
};

&camera_af_hw_node {
	vcamaf-supply = <&mt_pmic_vcamio_ldo_reg>;
	status = "okay";
};

&mtkfb {
	pinctrl-names = "lcd_bias_enp1_gpio", "lcd_bias_enp0_gpio",
		"lcd_bias_enn1_gpio", "lcd_bias_enn0_gpio",
		"lcm_rst_out1_gpio", "lcm_rst_out0_gpio",
		"mode_te_te";
	pinctrl-0 = <&mtkfb_pins_lcd_bias_enp1>;
	pinctrl-1 = <&mtkfb_pins_lcd_bias_enp0>;
	pinctrl-2 = <&mtkfb_pins_lcd_bias_enn1>;
	pinctrl-3 = <&mtkfb_pins_lcd_bias_enn0>;
	pinctrl-4 = <&mtkfb_pins_lcm_rst_out1_gpio>;
	pinctrl-5 = <&mtkfb_pins_lcm_rst_out0_gpio>;
	pinctrl-6 = <&mtkfb_pins_lcm_dsi_te>;
	status = "okay";
};
&dispsys_config {
	pinctrl-names =
		"lcm_rst_out1_gpio", "lcm_rst_out0_gpio",
		"mode_te_te";
	pinctrl-0 = <&mtkfb_pins_lcm_rst_out1_gpio>;
	pinctrl-1 = <&mtkfb_pins_lcm_rst_out0_gpio>;
	pinctrl-2 = <&mtkfb_pins_lcm_dsi_te>;
	status = "okay";

		helper-value = <0>, /*MTK_DRM_OPT_STAGE*/
			<1>, /*MTK_DRM_OPT_USE_CMDQ*/
			<1>, /*MTK_DRM_OPT_USE_M4U*/
			<0>, /*MTK_DRM_OPT_SODI_SUPPORT*/
			<1>, /*MTK_DRM_OPT_IDLE_MGR*/
			<0>, /*MTK_DRM_OPT_IDLEMGR_SWTCH_DECOUPLE*/
			<1>, /*MTK_DRM_OPT_IDLEMGR_BY_REPAINT*/
			<0>, /*MTK_DRM_OPT_IDLEMGR_ENTER_ULPS*/
			<0>, /*MTK_DRM_OPT_IDLEMGR_KEEP_LP11*/
			<0>, /*MTK_DRM_OPT_DYNAMIC_RDMA_GOLDEN_SETTING*/
			<1>, /*MTK_DRM_OPT_IDLEMGR_DISABLE_ROUTINE_IRQ*/
			<0>, /*MTK_DRM_OPT_MET_LOG*/
			<1>, /*MTK_DRM_OPT_USE_PQ*/
			<1>, /*MTK_DRM_OPT_ESD_CHECK_RECOVERY*/
			<1>, /*MTK_DRM_OPT_ESD_CHECK_SWITCH*/
			<1>, /*MTK_DRM_OPT_PRESENT_FENCE*/
			<0>, /*MTK_DRM_OPT_RDMA_UNDERFLOW_AEE*/
			<1>, /*MTK_DRM_OPT_DSI_UNDERRUN_AEE*/
			<1>, /*MTK_DRM_OPT_HRT*/
			<1>, /*MTK_DRM_OPT_HRT_MODE*/
			<0>, /*MTK_DRM_OPT_DELAYED_TRIGGER*/
			<1>, /*MTK_DRM_OPT_OVL_EXT_LAYER*/
			<0>, /*MTK_DRM_OPT_AOD*/
			<1>, /*MTK_DRM_OPT_RPO*/
			<0>, /*MTK_DRM_OPT_DUAL_PIPE*/
			<0>, /*MTK_DRM_OPT_DC_BY_HRT*/
			<0>, /*MTK_DRM_OPT_OVL_WCG*/
			<0>, /*MTK_DRM_OPT_OVL_SBCH*/
			<1>, /*MTK_DRM_OPT_COMMIT_NO_WAIT_VBLANK*/
			<0>, /*MTK_DRM_OPT_MET*/
			<0>, /*MTK_DRM_OPT_REG_PARSER_RAW_DUMP*/
			<0>, /*MTK_DRM_OPT_VP_PQ*/
			<0>, /*MTK_DRM_OPT_GAME_PQ*/
			<0>, /*MTK_DRM_OPT_MMPATH*/
			<1>, /*MTK_DRM_OPT_HBM*/
			<1>, /*MTK_DRM_OPT_VDS_PATH_SWITCH*/
			<0>, /*MTK_DRM_OPT_LAYER_REC*/
			<1>, /*MTK_DRM_OPT_CLEAR_LAYER*/
			<1>, /*MTK_DRM_OPT_LFR*/
			<0>; /*MTK_DRM_OPT_SF_PF*/
};
&dsi0 {
	status = "okay";
	#address-cells = <1>;
	#size-cells = <0>;
	panel6@0 {
		compatible = "20151,samsung,dphy,vdo";
		reg = <0>;
		pm-enable-gpios = <&pio 84 0>;
		reset-gpios = <&pio 86 0>;
		bias-gpios = <&pio 137 0>;
		pinctrl-names = "default";
		port {
			panel_in6: endpoint {
				remote-endpoint = <&dsi_out>;
			};
		};
	};
	ports {
		port {
			dsi_out: endpoint {
				remote-endpoint = <&panel_in6>;
			};
		};
	};
};

/* accdet start */
&accdet {
	/* accdet micbias voltage: 0x09:2.85v 0x08:2.8v 0x07,
	 * 2.7v;0x05,2.5v;0x02,1.9v
	 */
	accdet-mic-vol = <8>;
	/* accdet pwm_width, pwm_thresh, fall_delay, rise_delay
	 * debounce0, debounce1, debounce3, debounce4
	 * eint pwm_width, eint pwm_thresh
	 * eint deb(debounce0, debounce1, debounce2, debounce3), inv_debounce
	 */

        //#ifdef OPLUS_ARCH_EXTENDS
        headset-mode-setting = <0x500 0x500 1 0x1f0
                                0x2000 0x800 0x2000 0x44
                                0x0 0x7
                                0x5 0x9 0x9 0xd 0xe>;
        //#else /* OPLUS_ARCH_EXTENDS  */
        /*headset-mode-setting = <0x500 0x500 1 0x1f0
         *                      0x800 0x800 0x20 0x44
         *                      0x4 0x1
         *                      0x5 0x3 0x3 0x5 0xe>;
         */
         //#endif /* OPLUS_ARCH_EXTENDS  */

	accdet-plugout-debounce = <1>;
	/*1:ACC mode, 2:low cost without in bias, 6:low cost with in bias*/
	accdet-mic-mode = <2>;
	/*0--MD_MAX--UP_MAX--DW_MAX*/
	//#ifdef OPLUS_ARCH_EXTENDS
	headset-three-key-threshold = <0 82 170 306>;
	//#else /* OPLUS_ARCH_EXTENDS  */
	//headset-three-key-threshold = <0 80 220 400>;
	//#endif /* OPLUS_ARCH_EXTENDS  */
	headset-three-key-threshold-CDD = <0 121 192 600>;
	/*0--MD_MAX--VOICE_MAX--UP_MAX--DW_MAX*/
	headset-four-key-threshold = <0 58 121 192 400>;

        //#ifdef OPLUS_ARCH_EXTENDS
	/* moisture HW mode config start. Enable moisture detection or not
	 * default use HW mode for moisture detection
	 */
	moisture_detect_enable = <1>;
        //#endif /* OPLUS_ARCH_EXTENDS  */
	/* select VTH to 2v and 500k, use internal resitance */
	eint_use_ext_res = <0>;
        //#ifdef OPLUS_ARCH_EXTENDS
	/* enable eint detection mode, if moisture detection enable
	 * eint_detect_mode = moisture_detect_mode;otherwise, select
	 * eint_detect_mode = 4 as DEFAULT
	 */
	eint_detect_mode = <5>;
	/* enable moisture detection mode, if moisture detection enable
	 * eint_detect_mode = moisture_detect_mode
	 */
	moisture_detect_mode = <5>;
	/* select 0: 2.8V; 1: 2.4V; 2: 2V; 3: VTH=MVTH(VTH2) */
	moisture_comp_vth = <2>;
	/* vref2 voltage for different water impedance */
	moisture_comp_vref2 = <2>;
	/* moisture HW mode config end */

	/* moisture SW mode config start, use external resister or not.
	 * DEFAULT NOT NEED
	 */
	moisture_use_ext_res = <0>;
	/* moisture external resister ohm, SW mode by auxadc */
	moisture-external-r = <2000000>;
	/* moisture internal resister ohm, SW mode by auxadc */
	moisture-internal-r = <47000>;
	/* moisture of water resister ohm, SW mode by auxadc*/
	moisture-water-r = <10000>;
	/* moisture SW mode config end */
        //#endif /* OPLUS_ARCH_EXTENDS  */
	status = "okay";
};
/* accdet end */

/* IRTX GPIO Start */
&irtx_pwm {
	pinctrl-names = "irtx_gpio_led_default", "irtx_gpio_led_set";
	pinctrl-0 = <&irtx_gpio_led_default>;
	pinctrl-1 = <&irtx_gpio_led_set>;
	status = "okay";
};
&pio {
	/* IRTX GPIO Settings -Start */
	/* default: GPIO0, output, high */
	irtx_gpio_led_default:irtx_gpio_led_def@gpio57 {
		pins_cmd_dat {
			pinmux = <PINMUX_GPIO57__FUNC_GPIO57>;
			slew-rate = <1>;
			bias-disable;
			output-low;
			input-schmitt-enable = <0>;
		};
	};

	irtx_gpio_led_set:irtx_gpio_led_set@gpio57 {
		pins_cmd_dat {
			pinmux = <PINMUX_GPIO57__FUNC_PWM_3>;
			slew-rate = <1>;
			output-high;
		};
	};
}; /* IRTX GPIO Settings -End */

#endif

//#ifdef OPLUS_BUG_STABILITY
#include "mediatek/mt6853-sia81xx-i2c.dtsi"
//#endif

/* FINGERPRINT start */
//ifdef OPLUS_FEATURE_FINGERPRINT
&oplus_fp_common {
    compatible = "oplus,fp_common"; //Manufacture, and Model
    oplus,fp_gpio_num = <1>;
    oplus,fp_gpio_0 = <&pio 41 0x0>;
    pinctrl-names = "default";
    pinctrl-0 = <&gpio_id0_default>;
    goodix_optical {
        oplus,fp-id = <1>; /* fp id mapping table */
        vendor-chip = <11>; /* please refer to the struct fp_vendor_t in oplus_fp_commmon.n */
        eng-menu = "-1,-1"; /* represents SNR, inclination test item in engineer menu, and 0/1 means off/on */
        chip-name = "G_OPTICAL_G3S";  /* /proc/fp_id, will be displayed in engineer menu  */
    };
    jiiov_0302 {
        oplus,fp-id = <0>; // fp id mapping table
        vendor-chip = <23>; // please refer to the struct fp_vendor_t in oplus_fp_commmon.n
        eng-menu = "-1,-1"; // represents SNR, inclination test item in engineer menu, and 0/1 means off/on
        chip-name = "JIIOV_0302";  // /proc/fp_id, will be displayed in engineer menu
    };
};

&pio{
	gpio_id0_default: gpio_id0_default {
		pins_cmd_dat {
			pinmux = <PINMUX_GPIO41__FUNC_GPIO41>;
			input;
			bias-pull-up;
			input-enable;
		};
	};
};

&jiiov_fp {
	anc,gpio_irq = <&pio 7 0x00>;
	anc,gpio_rst = <&pio 6 0x00>;
	anc,enable-via-gpio;
	anc,gpio_pwr = <&pio 133 0x00>;
	pinctrl-names = "anc_reset_reset", "anc_reset_active", "anc_irq_active";
	pinctrl-0 = <&jiiov_fp_reset_output_low>;
	pinctrl-1 = <&jiiov_fp_reset_output_high>, <&jiiov_fp_gpio_clk>, <&jiiov_fp_gpio_mosi>, <&jiiov_fp_gpio_miso>, <&jiiov_fp_gpio_cs>;
	pinctrl-2 = <&jiiov_fp_irq_active>;
	status = "okay";
};

&pio{
jiiov_fp_reset_output_low: jiiov_fp_reset_output_low {
				pins_cmd_dat {
					pinmux = <PINMUX_GPIO6__FUNC_GPIO6>;
					slew-rate = <1>;
					output-low;
				};
			};
jiiov_fp_reset_output_high: jiiov_fp_reset_output_high {
				pins_cmd_dat {
					pinmux = <PINMUX_GPIO6__FUNC_GPIO6>;
					slew-rate = <1>;
					output-high;
				};
			};
jiiov_fp_gpio_clk: jiiov_fp_gpio_clk {
				pins_cmd_dat {
					pinmux = <PINMUX_GPIO28__FUNC_SPI5_CLK>;
					drive-strength = <2>;
				};
			};
jiiov_fp_gpio_mosi: jiiov_fp_gpio_mosi {
				pins_cmd_dat {
					pinmux = <PINMUX_GPIO30__FUNC_SPI5_MO>;
					drive-strength = <2>;
				};
			};
jiiov_fp_gpio_miso: jiiov_fp_gpio_miso {
				pins_cmd_dat {
					pinmux = <PINMUX_GPIO31__FUNC_SPI5_MI>;
					drive-strength = <3>;
				};
			};
jiiov_fp_gpio_cs: jiiov_fp_gpio_cs {
				pins_cmd_dat {
					pinmux = <PINMUX_GPIO29__FUNC_SPI5_CSB>;
					drive-strength = <2>;
				};
			};
jiiov_fp_irq_active: jiiov_fp_irq_active {
				pins_cmd_dat {
					pinmux = <PINMUX_GPIO7__FUNC_GPIO7>;
					slew-rate = <0>;
					input-enable;
				};
			};
};

&goodix_fp {
	goodix,gpio_irq = <&pio 7 0x00>;
	goodix,gpio_reset = <&pio 6 0x00>;
	goodix,gpio_cs = <&pio 29 0x00>;
	pinctrl-names = "default", "gf_spi_drive_6mA", "gf_cs_func";
	pinctrl-0 = <&gpio_goodix_irq_default>, <&gpio_goodix_reset_default>;
	pinctrl-1 = <&gpio_goodix_clk_6mA>, <&gpio_goodix_mosi_6mA>, <&gpio_goodix_miso_6mA>, <&gpio_goodix_cs_6mA>;
	pinctrl-2 = <&gpio_goodix_cs_func>;
	status = "okay";
};

&spi5 {
#address-cells = <1>;
#size-cells = <0>;
status = "okay";
oplus_fp: fingerprint@0 {
		compatible = "oplus,oplus_fp";
		reg = <0>;
		spi-max-frequency = <8000000>;
		spi-id = <5>;
		spi-irq = <39>;
		spi-reg = <11019000>;
		pw_en_gpio = <&pio 133 0x00>;
		power-num = <1>;
		status = "okay";
		power_source_1 {
			power-mode = <2>;
			power-name = "pw_en_gpio";
			poweron-level = <1>;
			delay-time = <0>;
		};
	};
};
/* 1 = ldo power, refer to oplus_fp_common.h*/
&pio{
gpio_goodix_reset_default: gpio_goodix_reset_default {
				pins_cmd_dat {
					pinmux = <PINMUX_GPIO6__FUNC_GPIO6>;
					output-low;
				};
			};
gpio_goodix_irq_default: gpio_goodix_irq_default {
				pins_cmd_dat {
					pinmux = <PINMUX_GPIO7__FUNC_GPIO7>;
					bias-pull-down;
				};
			};
gpio_goodix_clk_6mA: gpio_goodix_clk_6mA {
				pins_cmd_dat {
					pinmux = <PINMUX_GPIO28__FUNC_SPI5_CLK>;
					drive-strength = <2>;
				};
			};
gpio_goodix_mosi_6mA: gpio_goodix_mosi_6mA {
				pins_cmd_dat {
					pinmux = <PINMUX_GPIO30__FUNC_SPI5_MO>;
					drive-strength = <2>;
				};
			};
gpio_goodix_miso_6mA: gpio_goodix_miso_6mA {
				pins_cmd_dat {
					pinmux = <PINMUX_GPIO31__FUNC_SPI5_MI>;
					drive-strength = <3>;
				};
			};
gpio_goodix_cs_6mA: gpio_goodix_cs_6mA {
				pins_cmd_dat {
					pinmux = <PINMUX_GPIO29__FUNC_SPI5_CSB>;
					drive-strength = <2>;
				};
			};
gpio_goodix_cs_func: gpio_goodix_cs_func {
				pins_cmd_dat {
					pinmux = <PINMUX_GPIO29__FUNC_SPI5_CSB>;
					drive-strength = <2>;
				};
			};
};
//#endif
&msdc1 {
    cd-gpios = <&pio 12 0>;
    status = "okay";
    vmmc-supply = <&mt_pmic_vmch_ldo_reg>;
};
&mt6360_ldo {
	sdcard_det_en = <1>;
	sdcard_hlact = <0>;
};

//#ifdef OPLUS_FEATURE_SWTP
&swtp {
    compatible = "mediatek, swtp-eint";
};
//#endif  /*OPLUS_FEATURE_SWTP*/

/*End of this file, DO NOT ADD ANYTHING HERE*/

